VERSION ""

NS_ :

BS_:

BU_: PRBMS

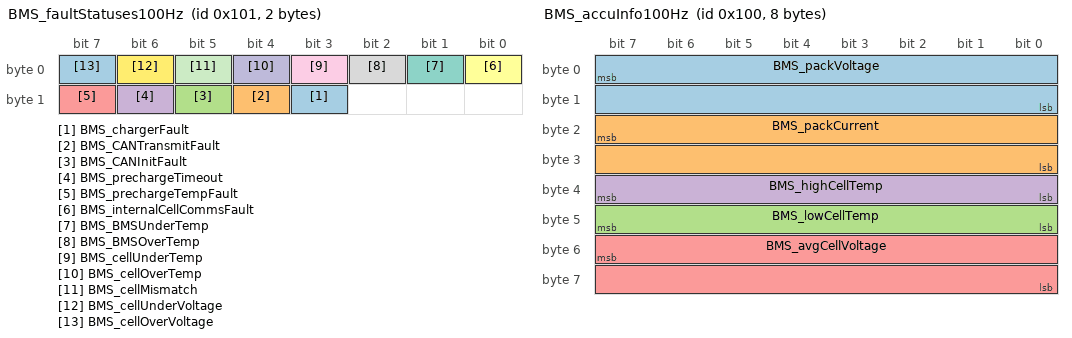
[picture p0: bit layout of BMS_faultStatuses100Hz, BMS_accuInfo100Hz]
BO_ 257 BMS_faultStatuses100Hz: 2 PRBMS
 SG_ BMS_chargerFault : 11|1@0+ (1,0) [0|0] "" Vector__XXX
 SG_ BMS_CANTransmitFault : 12|1@0+ (1,0) [0|0] "" Vector__XXX
 SG_ BMS_CANInitFault : 13|1@0+ (1,0) [0|0] "" Vector__XXX
 SG_ BMS_prechargeTimeout : 14|1@0+ (1,0) [0|0] "" Vector__XXX
 SG_ BMS_prechargeTempFault : 15|1@0+ (1,0) [0|0] "" Vector__XXX
 SG_ BMS_internalCellCommsFault : 0|1@0+ (1,0) [0|0] "" Vector__XXX
 SG_ BMS_BMSUnderTemp : 1|1@0+ (1,0) [0|0] "" Vector__XXX
 SG_ BMS_BMSOverTemp : 2|1@0+ (1,0) [0|0] "" Vector__XXX
 SG_ BMS_cellUnderTemp : 3|1@0+ (1,0) [0|0] "" Vector__XXX
 SG_ BMS_cellOverTemp : 4|1@0+ (1,0) [0|0] "" Vector__XXX
 SG_ BMS_cellMismatch : 5|1@0+ (1,0) [0|0] "" Vector__XXX
 SG_ BMS_cellUnderVoltage : 6|1@0+ (1,0) [0|0] "" Vector__XXX
 SG_ BMS_cellOverVoltage : 7|1@0+ (1,0) [0|1] "" Vector__XXX

BO_ 256 BMS_accuInfo100Hz: 8 PRBMS
 SG_ BMS_packVoltage : 7|16@0+ (0.1,0) [0|6553.5] "V" Vector__XXX
 SG_ BMS_packCurrent : 23|16@0+ (0.1,0) [0|6553.5] "A" Vector__XXX
 SG_ BMS_lowCellTemp : 47|8@0+ (1,0) [0|255] "C" Vector__XXX
 SG_ BMS_highCellTemp : 39|8@0+ (1,0) [0|255] "C" Vector__XXX
 SG_ BMS_avgCellVoltage : 55|16@0+ (0.001,0) [0|0] "V" Vector__XXX

BA_DEF_  "BusType" STRING ;
BA_DEF_DEF_  "BusType" "CAN";
